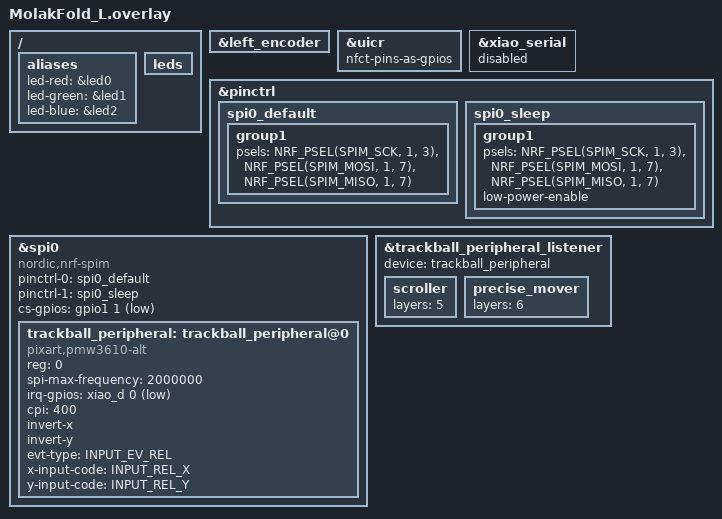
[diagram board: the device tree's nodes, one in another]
#include "MolakFold.dtsi"
#include <input/processors.dtsi>
#include <zephyr/dt-bindings/input/input-event-codes.h>

&left_encoder {
    status = "okay";
};

&uicr {
    nfct-pins-as-gpios;
};

&xiao_serial {
    status = "disabled";
};

&pinctrl {
    spi0_default: spi0_default {
        group1 {
            psels = <NRF_PSEL(SPIM_SCK, 1, 3)>,
                <NRF_PSEL(SPIM_MOSI, 1, 7)>,
                <NRF_PSEL(SPIM_MISO, 1, 7)>;
        };
    };

    spi0_sleep: spi0_sleep {
        group1 {
            psels = <NRF_PSEL(SPIM_SCK, 1, 3)>,
                <NRF_PSEL(SPIM_MOSI, 1, 7)>,
                <NRF_PSEL(SPIM_MISO, 1, 7)>;
            low-power-enable;
        };
    };
};

&spi0 {
    status = "okay";
    compatible = "nordic,nrf-spim";
    pinctrl-0 = <&spi0_default>;
    pinctrl-1 = <&spi0_sleep>;
    pinctrl-names = "default", "sleep";
    cs-gpios = <&gpio1 1 GPIO_ACTIVE_LOW>;

    trackball_peripheral: trackball_peripheral@0 {
        status = "okay";
        compatible = "pixart,pmw3610-alt";
        reg = <0>;
        spi-max-frequency = <2000000>;
        irq-gpios = <&xiao_d 0 (GPIO_ACTIVE_LOW | GPIO_PULL_UP)>;
        cpi = <400>;
        invert-x;
        invert-y;
        evt-type = <INPUT_EV_REL>;
        x-input-code = <INPUT_REL_X>;
        y-input-code = <INPUT_REL_Y>;
    };
};

&trackball_peripheral_listener {
    status = "okay";
    device = <&trackball_peripheral>;
    scroller {
        layers = <5>;
    };
    precise_mover {
        layers = <6>;
    };
};

// LED aliases for zmk-rgbled-widget (xiao_ble onboard RGB: R=P0.26, G=P0.30, B=P0.06)
/ {
    aliases {
        led-red = &led0;
        led-green = &led1;
        led-blue = &led2;
    };

    leds {
        status = "okay";
    };
};
